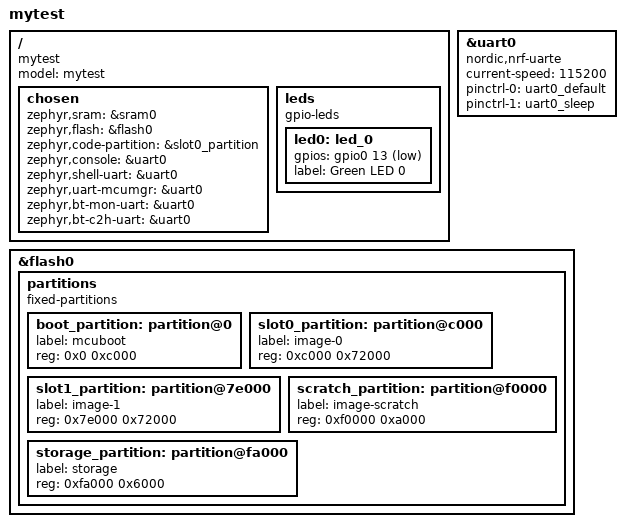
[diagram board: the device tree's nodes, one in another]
// Copyright (c) 2023 Nordic Semiconductor ASA
// SPDX-License-Identifier: Apache-2.0

/dts-v1/;
#include <nordic/nrf52840_qiaa.dtsi>
#include "mytest-pinctrl.dtsi"

/ {
	model = "mytest";
	compatible = "mytest";

	chosen {
		zephyr,sram = &sram0;
		zephyr,flash = &flash0;
		zephyr,code-partition = &slot0_partition;
		zephyr,console = &uart0;
		zephyr,shell-uart = &uart0;
		zephyr,uart-mcumgr = &uart0;
		zephyr,bt-mon-uart = &uart0;
		zephyr,bt-c2h-uart = &uart0;
	};

	leds {
		compatible = "gpio-leds";
		led0: led_0 {
			gpios = <&gpio0 13 GPIO_ACTIVE_LOW>;
			label = "Green LED 0";
		};
	};
};

&uart0 {
	compatible = "nordic,nrf-uarte";
	status = "okay";
	current-speed = <115200>;
	pinctrl-0 = <&uart0_default>;
	pinctrl-1 = <&uart0_sleep>;
	pinctrl-names = "default", "sleep";
};


&flash0 {
	partitions {
		compatible = "fixed-partitions";
		#address-cells = <1>;
		#size-cells = <1>;

		boot_partition: partition@0 {
			label = "mcuboot";
			reg = <0x0 0xc000>;
		};
		slot0_partition: partition@c000 {
			label = "image-0";
			reg = <0xc000 0x72000>;
		};
		slot1_partition: partition@7e000 {
			label = "image-1";
			reg = <0x7e000 0x72000>;
		};
		scratch_partition: partition@f0000 {
			label = "image-scratch";
			reg = <0xf0000 0xa000>;
		};
		storage_partition: partition@fa000 {
			label = "storage";
			reg = <0xfa000 0x6000>;
		};
	};
};

